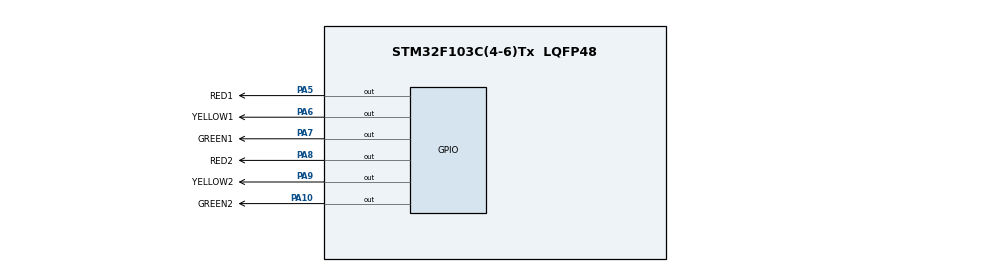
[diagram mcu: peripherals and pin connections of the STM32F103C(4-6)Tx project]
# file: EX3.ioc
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Mcu.Family=STM32F1
Mcu.Name=STM32F103C(4-6)Tx
Mcu.Package=LQFP48
NVIC.PriorityGroup=NVIC_PRIORITYGROUP_4
PA10.GPIO_Label=GREEN2
PA10.Signal=GPIO_Output
PA5.GPIO_Label=RED1
PA5.Signal=GPIO_Output
PA6.GPIO_Label=YELLOW1
PA6.Signal=GPIO_Output
PA7.GPIO_Label=GREEN1
PA7.Signal=GPIO_Output
PA8.GPIO_Label=RED2
PA8.Signal=GPIO_Output
PA9.GPIO_Label=YELLOW2
PA9.Signal=GPIO_Output
ProjectManager.HeapSize=0x200
ProjectManager.StackSize=0x400
ProjectManager.TargetToolchain=STM32CubeIDE
RCC.APB1Freq_Value=8000000
RCC.APB2Freq_Value=8000000
VP_SYS_VS_ND.Mode=No_Debug
board=custom

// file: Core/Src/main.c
/* USER CODE BEGIN Header */
/**
  ******************************************************************************
  * @file           : main.c
  * @brief          : Main program body
  ******************************************************************************
  * @attention
  *
  * <h2><center>&copy; Copyright (c) 2024 STMicroelectronics.
  * All rights reserved.</center></h2>
  *
  * This software component is licensed by ST under BSD 3-Clause license,
  * the "License"; You may not use this file except in compliance with the
  * License. You may obtain a copy of the License at:
  *                        opensource.org/licenses/BSD-3-Clause
  *
  ******************************************************************************
  */
/* USER CODE END Header */
#include "main.h"

void SystemClock_Config(void);
static void MX_GPIO_Init(void);

int main(void)
{

  /* MCU Configuration--------------------------------------------------------*/

  /* Reset of all peripherals, Initializes the Flash interface and the Systick. */
  HAL_Init();

  /* Configure the system clock */
  SystemClock_Config();

  /* Initialize all configured peripherals */
  MX_GPIO_Init();
  /* USER CODE BEGIN 2 */

  typedef enum LightState{
	  RED1_GREEN2,
	  RED1_YELLOW2,
	  GREEN1_RED2,
	  YELLOW1_RED2
  } TrafficLightState;

  void turnon(int Pin){
	  HAL_GPIO_WritePin(GPIOA, Pin, SET); //mo phong lay chan keo len noi dat vi vay tin hieu 1 thi den sang
  }

  void turnoff(int Pin){
	  HAL_GPIO_WritePin(GPIOA, Pin, RESET);
  }

  /* USER CODE END 2 */
  const int redTime = 5;
  const int yellowTime = 2;
  const int greenTime = 3;

  int counter = greenTime;

  TrafficLightState currentState = RED1_GREEN2;
  TrafficLightState nextState;
  /* Infinite loop */
  while (1)
  {
	  switch (currentState){
	  case RED1_GREEN2:
		  turnoff(YELLOW1_Pin);
		  turnoff(RED2_Pin);
	  	  turnon(RED1_Pin);
	  	  turnon(GREEN2_Pin);
	  	  counter--;
	  	  if (counter <= 0){
	  		  nextState = RED1_YELLOW2;
	  		  counter = yellowTime;
	  	  }
	  break;
	  case RED1_YELLOW2:
		  turnoff(GREEN2_Pin);
		  turnon(RED1_Pin);
		  turnon(YELLOW2_Pin);
		  counter--;
		  if (counter <= 0){
			  nextState = GREEN1_RED2;
			  counter = greenTime;
		  }
	  break;
	  case GREEN1_RED2:
		  turnoff(YELLOW2_Pin);
		  turnoff(RED1_Pin);
		  turnon(GREEN1_Pin);
		  turnon(RED2_Pin);
		  counter--;
		  if (counter <= 0){
			  nextState = YELLOW1_RED2;
			  counter = yellowTime;
		  }
	  break;
	  case YELLOW1_RED2:
		  turnoff(GREEN1_Pin);
		  turnon(YELLOW1_Pin);
		  turnon(RED2_Pin);
		  counter--;
		  if (counter <= 0){
			  nextState = RED1_GREEN2;
			  counter = greenTime;
		  }
	  break;
	  }
	  currentState = nextState;
	  HAL_Delay(1000);
  }
}

void SystemClock_Config(void)
{
  RCC_OscInitTypeDef RCC_OscInitStruct = {0};
  RCC_ClkInitTypeDef RCC_ClkInitStruct = {0};

  /** Initializes the RCC Oscillators according to the specified parameters
  * in the RCC_OscInitTypeDef structure.
  */
  RCC_OscInitStruct.OscillatorType = RCC_OSCILLATORTYPE_HSI;
  RCC_OscInitStruct.HSIState = RCC_HSI_ON;
  RCC_OscInitStruct.HSICalibrationValue = RCC_HSICALIBRATION_DEFAULT;
  RCC_OscInitStruct.PLL.PLLState = RCC_PLL_NONE;
  if (HAL_RCC_OscConfig(&RCC_OscInitStruct) != HAL_OK)
  {
    Error_Handler();
  }
  /** Initializes the CPU, AHB and APB buses clocks
  */
  RCC_ClkInitStruct.ClockType = RCC_CLOCKTYPE_HCLK|RCC_CLOCKTYPE_SYSCLK
                              |RCC_CLOCKTYPE_PCLK1|RCC_CLOCKTYPE_PCLK2;
  RCC_ClkInitStruct.SYSCLKSource = RCC_SYSCLKSOURCE_HSI;
  RCC_ClkInitStruct.AHBCLKDivider = RCC_SYSCLK_DIV1;
  RCC_ClkInitStruct.APB1CLKDivider = RCC_HCLK_DIV1;
  RCC_ClkInitStruct.APB2CLKDivider = RCC_HCLK_DIV1;

  if (HAL_RCC_ClockConfig(&RCC_ClkInitStruct, FLASH_LATENCY_0) != HAL_OK)
  {
    Error_Handler();
  }
}

static void MX_GPIO_Init(void)
{
  GPIO_InitTypeDef GPIO_InitStruct = {0};

  /* GPIO Ports Clock Enable */
  __HAL_RCC_GPIOA_CLK_ENABLE();

  /*Configure GPIO pin Output Level */
  HAL_GPIO_WritePin(GPIOA, RED1_Pin|YELLOW1_Pin|GREEN1_Pin|RED2_Pin
                          |YELLOW2_Pin|GREEN2_Pin, GPIO_PIN_RESET);

  /*Configure GPIO pins : RED1_Pin YELLOW1_Pin GREEN1_Pin RED2_Pin
                           YELLOW2_Pin GREEN2_Pin */
  GPIO_InitStruct.Pin = RED1_Pin|YELLOW1_Pin|GREEN1_Pin|RED2_Pin
                          |YELLOW2_Pin|GREEN2_Pin;
  GPIO_InitStruct.Mode = GPIO_MODE_OUTPUT_PP;
  GPIO_InitStruct.Pull = GPIO_NOPULL;
  GPIO_InitStruct.Speed = GPIO_SPEED_FREQ_LOW;
  HAL_GPIO_Init(GPIOA, &GPIO_InitStruct);

}

void Error_Handler(void)
{
  __disable_irq();
  while (1)
  {
  }
}

/************************ (C) COPYRIGHT STMicroelectronics *****END OF FILE****/
